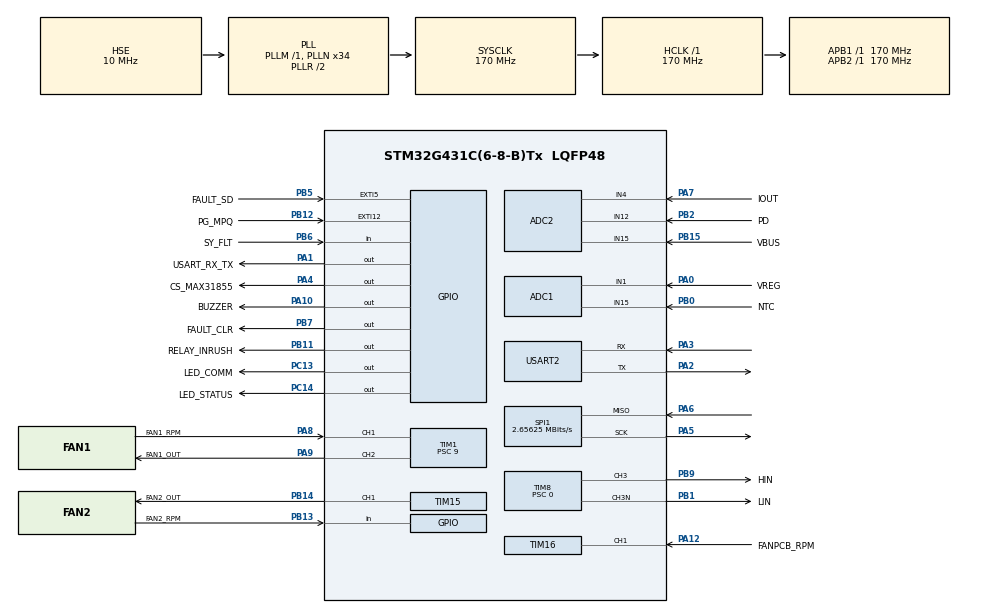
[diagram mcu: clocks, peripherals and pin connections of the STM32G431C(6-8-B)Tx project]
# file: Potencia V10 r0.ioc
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ADC1.Channel-0\#ChannelRegularConversion=ADC_CHANNEL_1
ADC1.Channel-1\#ChannelRegularConversion=ADC_CHANNEL_15
ADC1.ContinuousConvMode=ENABLE
ADC1.DMAContinuousRequests=ENABLE
ADC1.EOCSelection=ADC_EOC_SEQ_CONV
ADC1.LowPowerAutoWait=DISABLE
ADC1.NbrOfConversion=2
ADC1.NbrOfConversionFlag=1
ADC1.OffsetNumber-0\#ChannelRegularConversion=ADC_OFFSET_NONE
ADC1.OffsetNumber-1\#ChannelRegularConversion=ADC_OFFSET_NONE
ADC1.Overrun=ADC_OVR_DATA_OVERWRITTEN
ADC1.Rank-0\#ChannelRegularConversion=1
ADC1.Rank-1\#ChannelRegularConversion=2
ADC1.SamplingTime-0\#ChannelRegularConversion=ADC_SAMPLETIME_247CYCLES_5
ADC1.SamplingTime-1\#ChannelRegularConversion=ADC_SAMPLETIME_247CYCLES_5
ADC1.master=1
ADC2.Channel-0\#ChannelRegularConversion=ADC_CHANNEL_4
ADC2.Channel-1\#ChannelRegularConversion=ADC_CHANNEL_12
ADC2.Channel-2\#ChannelRegularConversion=ADC_CHANNEL_15
ADC2.ContinuousConvMode=ENABLE
ADC2.DMAContinuousRequests=ENABLE
ADC2.EOCSelection=ADC_EOC_SEQ_CONV
ADC2.NbrOfConversion=3
ADC2.NbrOfConversionFlag=1
ADC2.OffsetNumber-0\#ChannelRegularConversion=ADC_OFFSET_NONE
ADC2.OffsetNumber-1\#ChannelRegularConversion=ADC_OFFSET_NONE
ADC2.OffsetNumber-2\#ChannelRegularConversion=ADC_OFFSET_NONE
ADC2.Overrun=ADC_OVR_DATA_OVERWRITTEN
ADC2.Rank-0\#ChannelRegularConversion=1
ADC2.Rank-1\#ChannelRegularConversion=2
ADC2.Rank-2\#ChannelRegularConversion=3
ADC2.SamplingTime-0\#ChannelRegularConversion=ADC_SAMPLETIME_92CYCLES_5
ADC2.SamplingTime-1\#ChannelRegularConversion=ADC_SAMPLETIME_92CYCLES_5
ADC2.SamplingTime-2\#ChannelRegularConversion=ADC_SAMPLETIME_92CYCLES_5
Dma.ADC1.0.Direction=DMA_PERIPH_TO_MEMORY
Dma.ADC1.0.EventEnable=DISABLE
Dma.ADC1.0.Instance=DMA1_Channel1
Dma.ADC1.0.MemDataAlignment=DMA_MDATAALIGN_WORD
Dma.ADC1.0.MemInc=DMA_MINC_ENABLE
Dma.ADC1.0.Mode=DMA_CIRCULAR
Dma.ADC1.0.PeriphDataAlignment=DMA_PDATAALIGN_WORD
Dma.ADC1.0.PeriphInc=DMA_PINC_DISABLE
Dma.ADC1.0.Polarity=HAL_DMAMUX_REQ_GEN_RISING
Dma.ADC1.0.Priority=DMA_PRIORITY_LOW
Dma.ADC1.0.RequestNumber=1
Dma.ADC1.0.SignalID=NONE
Dma.ADC1.0.SyncEnable=DISABLE
Dma.ADC1.0.SyncPolarity=HAL_DMAMUX_SYNC_NO_EVENT
Dma.ADC1.0.SyncRequestNumber=1
Dma.ADC1.0.SyncSignalID=NONE
Dma.ADC2.1.Direction=DMA_PERIPH_TO_MEMORY
Dma.ADC2.1.EventEnable=DISABLE
Dma.ADC2.1.Instance=DMA1_Channel2
Dma.ADC2.1.MemDataAlignment=DMA_MDATAALIGN_WORD
Dma.ADC2.1.MemInc=DMA_MINC_ENABLE
Dma.ADC2.1.Mode=DMA_CIRCULAR
Dma.ADC2.1.PeriphDataAlignment=DMA_PDATAALIGN_WORD
Dma.ADC2.1.PeriphInc=DMA_PINC_DISABLE
Dma.ADC2.1.Polarity=HAL_DMAMUX_REQ_GEN_RISING
Dma.ADC2.1.Priority=DMA_PRIORITY_LOW
Dma.ADC2.1.RequestNumber=1
Dma.ADC2.1.SignalID=NONE
Dma.ADC2.1.SyncEnable=DISABLE
Dma.ADC2.1.SyncPolarity=HAL_DMAMUX_SYNC_NO_EVENT
Dma.ADC2.1.SyncRequestNumber=1
Dma.ADC2.1.SyncSignalID=NONE
Dma.Request0=ADC1
Dma.Request1=ADC2
Dma.Request2=SPI1_RX
Dma.Request3=USART2_RX
Dma.Request4=USART2_TX
Dma.SPI1_RX.2.Direction=DMA_PERIPH_TO_MEMORY
Dma.SPI1_RX.2.EventEnable=DISABLE
Dma.SPI1_RX.2.Instance=DMA1_Channel3
Dma.SPI1_RX.2.MemDataAlignment=DMA_MDATAALIGN_BYTE
Dma.SPI1_RX.2.MemInc=DMA_MINC_ENABLE
Dma.SPI1_RX.2.Mode=DMA_NORMAL
Dma.SPI1_RX.2.PeriphDataAlignment=DMA_PDATAALIGN_BYTE
Dma.SPI1_RX.2.PeriphInc=DMA_PINC_DISABLE
Dma.SPI1_RX.2.Polarity=HAL_DMAMUX_REQ_GEN_RISING
Dma.SPI1_RX.2.Priority=DMA_PRIORITY_LOW
Dma.SPI1_RX.2.RequestNumber=1
Dma.SPI1_RX.2.SignalID=NONE
Dma.SPI1_RX.2.SyncEnable=DISABLE
Dma.SPI1_RX.2.SyncPolarity=HAL_DMAMUX_SYNC_NO_EVENT
Dma.SPI1_RX.2.SyncRequestNumber=1
Dma.SPI1_RX.2.SyncSignalID=NONE
Dma.USART2_RX.3.Direction=DMA_PERIPH_TO_MEMORY
Dma.USART2_RX.3.EventEnable=DISABLE
Dma.USART2_RX.3.Instance=DMA2_Channel1
Dma.USART2_RX.3.MemDataAlignment=DMA_MDATAALIGN_BYTE
Dma.USART2_RX.3.MemInc=DMA_MINC_ENABLE
Dma.USART2_RX.3.Mode=DMA_CIRCULAR
Dma.USART2_RX.3.PeriphDataAlignment=DMA_PDATAALIGN_BYTE
Dma.USART2_RX.3.PeriphInc=DMA_PINC_DISABLE
Dma.USART2_RX.3.Polarity=HAL_DMAMUX_REQ_GEN_RISING
Dma.USART2_RX.3.Priority=DMA_PRIORITY_HIGH
Dma.USART2_RX.3.RequestNumber=1
Dma.USART2_RX.3.SignalID=NONE
Dma.USART2_RX.3.SyncEnable=DISABLE
Dma.USART2_RX.3.SyncPolarity=HAL_DMAMUX_SYNC_NO_EVENT
Dma.USART2_RX.3.SyncRequestNumber=1
Dma.USART2_RX.3.SyncSignalID=NONE
Dma.USART2_TX.4.Direction=DMA_MEMORY_TO_PERIPH
Dma.USART2_TX.4.EventEnable=DISABLE
Dma.USART2_TX.4.Instance=DMA2_Channel2
Dma.USART2_TX.4.MemDataAlignment=DMA_MDATAALIGN_BYTE
Dma.USART2_TX.4.MemInc=DMA_MINC_ENABLE
Dma.USART2_TX.4.Mode=DMA_NORMAL
Dma.USART2_TX.4.PeriphDataAlignment=DMA_PDATAALIGN_BYTE
Dma.USART2_TX.4.PeriphInc=DMA_PINC_DISABLE
Dma.USART2_TX.4.Polarity=HAL_DMAMUX_REQ_GEN_RISING
Dma.USART2_TX.4.Priority=DMA_PRIORITY_HIGH
Dma.USART2_TX.4.RequestNumber=1
Dma.USART2_TX.4.SignalID=NONE
Dma.USART2_TX.4.SyncEnable=DISABLE
Dma.USART2_TX.4.SyncPolarity=HAL_DMAMUX_SYNC_NO_EVENT
Dma.USART2_TX.4.SyncRequestNumber=1
Dma.USART2_TX.4.SyncSignalID=NONE
Mcu.Family=STM32G4
Mcu.Name=STM32G431C(6-8-B)Tx
Mcu.Package=LQFP48
NVIC.DMA1_Channel1_IRQn=true\:0\:0\:false\:false\:true\:false\:true\:true
NVIC.DMA1_Channel2_IRQn=true\:0\:0\:false\:false\:true\:false\:true\:true
NVIC.DMA1_Channel3_IRQn=true\:0\:0\:false\:false\:true\:false\:true\:true
NVIC.DMA2_Channel1_IRQn=true\:0\:0\:false\:false\:true\:false\:true\:true
NVIC.DMA2_Channel2_IRQn=true\:0\:0\:false\:false\:true\:false\:true\:true
NVIC.EXTI15_10_IRQn=true\:0\:0\:false\:false\:true\:true\:true\:true
NVIC.EXTI9_5_IRQn=true\:0\:0\:false\:false\:true\:true\:true\:true
NVIC.PVD_PVM_IRQn=true\:0\:0\:false\:false\:true\:true\:true\:true
NVIC.PriorityGroup=NVIC_PRIORITYGROUP_4
NVIC.TIM1_UP_TIM16_IRQn=true\:0\:0\:true\:false\:true\:true\:true\:true
NVIC.TIM2_IRQn=true\:0\:0\:false\:false\:true\:true\:true\:true
NVIC.USART2_IRQn=true\:0\:0\:false\:false\:true\:true\:true\:true
PA0.GPIO_Label=VREG
PA0.Mode=IN1-Single-Ended
PA0.Signal=ADC1_IN1
PA1.GPIO_Label=USART_RX_TX
PA1.Signal=GPIO_Output
PA10.GPIO_Label=BUZZER
PA10.Signal=GPIO_Output
PA12.GPIO_Label=FANPCB_RPM
PA12.Signal=S_TIM16_CH1
PA13.Mode=Trace_Asynchronous_SW
PA13.Signal=SYS_JTMS-SWDIO
PA14.Mode=Trace_Asynchronous_SW
PA14.Signal=SYS_JTCK-SWCLK
PA2.Mode=Asynchronous
PA2.Signal=USART2_TX
PA3.Mode=Asynchronous
PA3.Signal=USART2_RX
PA4.GPIO_Label=CS_MAX31855
PA4.PinState=GPIO_PIN_SET
PA4.Signal=GPIO_Output
PA5.Mode=RX_Only_Simplex_Unidirect_Master
PA5.Signal=SPI1_SCK
PA6.Mode=RX_Only_Simplex_Unidirect_Master
PA6.Signal=SPI1_MISO
PA7.GPIO_Label=IOUT
PA7.Mode=IN4-Single-Ended
PA7.Signal=ADC2_IN4
PA8.GPIO_Label=FAN1_RPM
PA8.Signal=S_TIM1_CH1
PA9.GPIO_Label=FAN1_OUT
PA9.Signal=S_TIM1_CH2
PB0.GPIO_Label=NTC
PB0.Mode=IN15-Single-Ended
PB0.Signal=ADC1_IN15
PB1.GPIO_Label=LIN
PB1.Mode=PWM Generation3 CH3 CH3N
PB1.Signal=TIM8_CH3N
PB11.GPIO_Label=RELAY_INRUSH
PB11.Signal=GPIO_Output
PB12.GPIO_Label=PG_MPQ
PB12.GPIO_ModeDefaultEXTI=GPIO_MODE_IT_FALLING
PB12.Signal=GPXTI12
PB13.GPIO_Label=FAN2_RPM
PB13.Signal=GPIO_Input
PB14.GPIO_Label=FAN2_OUT
PB14.Signal=S_TIM15_CH1
PB15.GPIO_Label=VBUS
PB15.Mode=IN15-Single-Ended
PB15.Signal=ADC2_IN15
PB2.GPIO_Label=PD
PB2.Mode=IN12-Single-Ended
PB2.Signal=ADC2_IN12
PB3.Mode=Trace_Asynchronous_SW
PB3.Signal=SYS_JTDO-SWO
PB5.GPIO_Label=FAULT_SD
PB5.GPIO_ModeDefaultEXTI=GPIO_MODE_IT_FALLING
PB5.Signal=GPXTI5
PB6.GPIO_Label=SY_FLT
PB6.Signal=GPIO_Input
PB7.GPIO_Label=FAULT_CLR
PB7.PinState=GPIO_PIN_SET
PB7.Signal=GPIO_Output
PB9.GPIO_Label=HIN
PB9.Signal=S_TIM8_CH3
PC13.GPIO_Label=LED_COMM
PC13.Signal=GPIO_Output
PC14-OSC32_IN.GPIO_Label=LED_STATUS
PC14-OSC32_IN.Signal=GPIO_Output
PF0-OSC_IN.Mode=HSE-External-Oscillator
PF0-OSC_IN.Signal=RCC_OSC_IN
PF1-OSC_OUT.Mode=HSE-External-Oscillator
PF1-OSC_OUT.Signal=RCC_OSC_OUT
ProjectManager.HeapSize=0x200
ProjectManager.StackSize=0x400
ProjectManager.TargetToolchain=STM32CubeIDE
RCC.ADC12Freq_Value=170000000
RCC.AHBFreq_Value=170000000
RCC.APB1Freq_Value=170000000
RCC.APB1TimFreq_Value=170000000
RCC.APB2Freq_Value=170000000
RCC.APB2TimFreq_Value=170000000
RCC.CortexFreq_Value=170000000
RCC.EXTERNAL_CLOCK_VALUE=12288000
RCC.HCLKFreq_Value=170000000
RCC.HSE_VALUE=10000000
RCC.HSI48_VALUE=48000000
RCC.HSI_VALUE=16000000
RCC.LSE_VALUE=32768
RCC.PLLN=34
RCC.PLLSourceVirtual=RCC_PLLSOURCE_HSE
RCC.SYSCLKFreq_VALUE=170000000
RCC.SYSCLKSource=RCC_SYSCLKSOURCE_PLLCLK
RCC.USBFreq_Value=170000000
RCC.VCOOutputFreq_Value=340000000
SH.S_TIM15_CH1.0=TIM15_CH1,PWM Generation1 CH1
SH.S_TIM16_CH1.0=TIM16_CH1,Input_Capture1_from_TI1
SH.S_TIM1_CH1.0=TIM1_CH1,Input_Capture1_from_TI1
SH.S_TIM1_CH2.0=TIM1_CH2,PWM Generation2 CH2
SH.S_TIM8_CH3.0=TIM8_CH3,PWM Generation3 CH3 CH3N
SPI1.BaudRatePrescaler=SPI_BAUDRATEPRESCALER_64
SPI1.CalculateBaudRate=2.65625 MBits/s
SPI1.DataSize=SPI_DATASIZE_8BIT
SPI1.Direction=SPI_DIRECTION_2LINES_RXONLY
SPI1.Mode=SPI_MODE_MASTER
SPI1.TIMode=SPI_TIMODE_DISABLE
SPI1.VirtualType=VM_MASTER
TIM1.Channel-Input_Capture1_from_TI1=TIM_CHANNEL_1
TIM1.Channel-PWM\ Generation2\ CH2=TIM_CHANNEL_2
TIM1.OC2Preload_PWM=DISABLE
TIM1.PeriodNoDither=16999
TIM1.Prescaler=9
TIM15.Channel-PWM\ Generation1\ CH1=TIM_CHANNEL_1
TIM15.OC1Preload_PWM=DISABLE
TIM15.PeriodNoDither=16999
TIM15.Prescaler=9
TIM16.AutoReloadPreload=TIM_AUTORELOAD_PRELOAD_ENABLE
TIM16.Channel=TIM_CHANNEL_1
TIM16.ClockDivision=TIM_CLOCKDIVISION_DIV4
TIM16.ICPrescaler=TIM_ICPSC_DIV1
TIM2.PeriodNoDither=99
TIM2.Prescaler=1700
TIM8.AutoReloadPreload=TIM_AUTORELOAD_PRELOAD_DISABLE
TIM8.Channel-PWM\ Generation3\ CH3\ CH3N=TIM_CHANNEL_3
TIM8.DeadTime=1
TIM8.OC3Preload_PWM=DISABLE
TIM8.OCFastMode_PWM-PWM\ Generation3\ CH3\ CH3N=TIM_OCFAST_DISABLE
TIM8.OCMode_PWM-PWM\ Generation3\ CH3\ CH3N=TIM_OCMODE_PWM1
TIM8.PeriodNoDither=1700
TIM8.Prescaler=0
TIM8.PulseNoDither_3=100
USART2.VirtualMode-Asynchronous=VM_ASYNC
USART2.WordLength=WORDLENGTH_8B
VP_SYS_VS_DBSignals.Mode=DisableDeadBatterySignals
VP_TIM15_VS_ClockSourceINT.Mode=Internal
VP_TIM16_VS_ClockSourceINT.Mode=Enable_Timer
VP_TIM1_VS_ClockSourceINT.Mode=Internal
VP_TIM2_VS_ClockSourceINT.Mode=Internal
VP_TIM8_VS_ClockSourceINT.Mode=Internal
board=custom

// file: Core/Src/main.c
/* USER CODE BEGIN Header */
/**
 ******************************************************************************
 * @file           : main.c
 * @brief          : Main program body
 ******************************************************************************
 * @attention
 *
 * Copyright (c) 2022 STMicroelectronics.
 * All rights reserved.
 *
 * This software is licensed under terms that can be found in the LICENSE file
 * in the root directory of this software component.
 * If no LICENSE file comes with this software, it is provided AS-IS.
 *
 ******************************************************************************
 */
/* USER CODE END Header */
#include "main.h"

/* USER CODE BEGIN Includes */

#include <stdlib.h>
#include <string.h>
#include <stdbool.h>
#include <limits.h>

#include "NTC 10K 3989.h"
#include "Full Duplex USART r0.h"
#include "MAX31855 r0.h"
/* USER CODE END Includes */

/* USER CODE BEGIN PTD */

typedef union
{
	struct
	{
		unsigned Powerdown :1;
		unsigned Undervoltage :1;
		unsigned Overvoltage :1;
		unsigned MPQNpg :1;
		unsigned ErrorFanPcb :1;
		unsigned ErrorFan1 :1;
		unsigned Fault :1;
		unsigned ErrorNTCDissipator :1;
		unsigned Dummy :24;
	};
	uint32_t ExistError;
} t_FlagsErrors;

uint32_t SerialNumber;

volatile struct
{
	// PID Control
	int32_t kP;
	int32_t kI;
	int32_t kD;

	// Oven Config
	uint16_t MaxTemperatureOven;
	uint16_t MaxRPMFanOven;

	//PCB Config
	uint16_t MinVoltInput;
	uint16_t MaxVoltInput;

	uint16_t MinRPMFanPCB;
	uint16_t MaxTemperaturePCB;

} Config;
volatile struct
{
	uint16_t PowerVoltage; //
	uint16_t ControlVoltage; //
	uint16_t OutputVoltage; //
	uint16_t CurrentOutput; //

	int16_t TemperatureOven; //
	int16_t TemperaturePCB; //

	uint16_t FanRPMPCB; //
	uint16_t FanRPMOven1; //
	uint16_t FanRPMOven2; // todo: Include in new revision PCB

	uint32_t HourmeterHours; //
	uint8_t HourmeterMinutes; //

	t_FlagsErrors Errors; //
} Status;

volatile struct
{
	union
	{
		unsigned CalculateNTC :1;
		unsigned CalculatePD :1;
		unsigned CalculateVBUS :1;
		unsigned CalculateVREG :1;
		unsigned CalculateCURR :1;
		unsigned Error :5;
		unsigned Dummy :22;
	} Flags;
} sStatusPower;

enum
{
	ERROR_NONE = 0, ERROR_POWERDOWN, ERROR_UNDERVOLTAGE, ERROR_OVERVOLTAGE, ERROR_MPQ_NPG, //NPG = NOT POWER GOOD
	ERROR_FAN_PCB,
	ERROR_FAN1,
	ERROR_FAULT,
	ERROR_NTC_DISSIPATOR,
} eErros;

enum
{
	COMM_GET_STATUS = 0, COMM_GET_SERIAL_NUMBER,

	COMM_SET_CONFIGURATION, COMM_SET_SERIAL_NUMBER,
} eComm;

FD_t *FullDuplexSystem;

/* USER CODE END PTD */

/* USER CODE BEGIN PD */
/* ################# DEFINIÇÕES CÓDIGO	 	 ################# */

#define	HIGH			1
#define	LOW				0

/* ################# DEFINITIONS AD 		 ################# */
#define RES_AD			4095UL				// (2^12 - 1)
#define	VREF			33UL				//3,3V

/* ################# POWERDOWN DEFINITIONS 	 ################# */
#define POWERDOWN_VALUE 160 //16V
#define TIMEOUT_PD		500//ms
#define BUFFER_PD		10
#define RCIMA_PD		10000UL
#define RBAIXO_PD		1240UL
#define PD_MULT			((VREF * (RCIMA_PD + RBAIXO_PD))/((RES_AD * RBAIXO_PD)/PD_DIV))
#define PD_DIV			1000

/* ################# VBUS DEFINITIONS 		 ################# */
#define UNDERVOLTAGE_VALUE 		1000 		//100V
#define TIMEOUT_UNDERVOLTAGE	500			//ms
#define OVERVOLTAGE_VALUE 		1970 		//197V
#define TIMEOUT_OVERVOLTAGE		500			//ms
#define LOW_OPERATION	400					//40V
#define BUFFER_VBUS		10
#define RCIMA_VBUS		300000UL
#define RBAIXO_VBUS		3900UL
#define VBUS_MULT		((VREF * (RCIMA_VBUS + RBAIXO_VBUS))/((RES_AD * RBAIXO_VBUS) /VBUS_DIV))
#define VBUS_DIV		1000

/* ################# VREG DEFINITIONS 		 ################ */
#define BUFFER_VREG		10
#define RCIMA_VREG		300000UL
#define RBAIXO_VREG		3900UL
#define VREG_MULT		((VREF * (RCIMA_VREG + RBAIXO_VREG))/((RES_AD * RBAIXO_VREG) /VBUS_VREG))
#define VREG_DIV		1000

/* ################# CURR DEFINITIONS 		 ################# */
#define BUFFER_CURR		10
#define AD_0A			409 //bits //Todo: In future, change this value for calibration value
#define AD_SENSITIVY	124 //124 bits/A

/* ################# NTC DEFINITIONS 		 ################# */
#define	TEMPERATURE_SHORT_CIRCUIT	1200	//120°C
#define	TEMPERATURE_OPEN_CIRCUIT	-200	//-20°C
#define OVERTEMPERATURE_DISSIPATOR	800		//80°C
#define BUFFER_NTC	1000					//1000 leituras de AD

/* ################# DEFINITIONS GENERAL	 ################# */
#define PERIOD_LED					1000	//ms
#define PERIOD_LED_ERROR 			250		//ms
#define RELAY_INRUSH				300		//ms
#define FAN_PCB_TIMEOUT				5000	//ms
#define FAN_1_AND_2_TIMEOUT			5000	//ms

/* ################# COEFICIENTE ANGULAR SAIDA  ################# */
#define COEFF_A			1.0
#define COEFF_B			0.0

/* ################# DEFINES MAX31855  ################# */

/* USER CODE END PD */

ADC_HandleTypeDef hadc1;
ADC_HandleTypeDef hadc2;
DMA_HandleTypeDef hdma_adc1;
DMA_HandleTypeDef hdma_adc2;

SPI_HandleTypeDef hspi1;
DMA_HandleTypeDef hdma_spi1_rx;

TIM_HandleTypeDef htim1;
TIM_HandleTypeDef htim2;
TIM_HandleTypeDef htim8;
TIM_HandleTypeDef htim15;
TIM_HandleTypeDef htim16;

UART_HandleTypeDef huart2;
DMA_HandleTypeDef hdma_usart2_rx;
DMA_HandleTypeDef hdma_usart2_tx;

/* USER CODE BEGIN PV */
uint32_t Adc1Val[2], Adc2Val[3];
volatile uint16_t AdValuePD[BUFFER_PD] =
{ 0 }, AdValueVBUS[BUFFER_VBUS] =
{ 0 }, AdValueVREG[BUFFER_VREG] =
{ 0 }, AdValueNTC[BUFFER_NTC] =
{ 0 }, AdValueCURR[BUFFER_CURR] =
{ 0 };
uint16_t ValuePD = 0, ValueVBUS = 0, ValueVREG = 0;
int16_t ValueNTC = 0, ValueCURR = 0;
volatile uint16_t CntTimeoutPD = 0, CntTimeoutOvervoltage = 0, CntTimeoutUndervoltage = 0;
volatile uint8_t CntAdValuePD = 0, CntAdValueCURR = 0, CntAdValueVBUS = 0, CntAdValueVREG = 0, CntAdValueNTC = 0;
volatile uint16_t CntStatusLED = 0;
volatile uint16_t CntStatusLEDError = 0;
volatile uint16_t Cnt1ms = 0;
volatile uint32_t IC_FanPCB_Value1 = 0, IC_Fan1_Value1 = 0, IC_FanPCB_Value2 = 0, IC_Fan1_Value2 = 0, IC_FanPCB_Difference = 0, IC_Fan1_Difference = 0,
		IC_FanPCB_Frequency = 0, IC_Fan1_Frequency = 0;
volatile uint8_t IC_FanPCB_IsFirstCaptured = false, IC_Fan1_IsFirstCaptured = false;
volatile uint16_t IC_FanPCB_OvfTimer = 0, IC_Fan1_OvfTimer = 0, IC_FanPCB_RPM = 0, IC_Fan1_RPM = 0;
volatile uint16_t CntFanPCB = 0, CntFan1 = 0, CntRelayInrush = 0;
volatile uint8_t Cnt60s = 0;
/* USER CODE END PV */

void SystemClock_Config(void);
static void MX_GPIO_Init(void);
static void MX_DMA_Init(void);
static void MX_ADC1_Init(void);
static void MX_ADC2_Init(void);
static void MX_TIM2_Init(void);
static void MX_TIM16_Init(void);
static void MX_SPI1_Init(void);
static void MX_USART2_UART_Init(void);
static void MX_TIM8_Init(void);
static void MX_TIM1_Init(void);
static void MX_TIM15_Init(void);
/* USER CODE BEGIN PFP */
static void Hw_Buck_Init(void);
static void Hw_Buck_Deinit(void);
void HAL_GPIO_EXTI_Callback(uint16_t GPIO_Pin);
void HAL_TIM_PeriodElapsedCallback(TIM_HandleTypeDef *htim);
void DMACallbackADC1(DMA_HandleTypeDef *hdma);
void DMACallbackADC2(DMA_HandleTypeDef *hdma);

void HAL_TIM_IC_CaptureCallback(TIM_HandleTypeDef *htim);
static void StatusLEDControl(uint8_t ErrorCode);
static void SetOutputVoltage(uint16_t OutVoltage);
static void SetError(void);
/* USER CODE END PFP */

int main(void)
{

	/* MCU Configuration--------------------------------------------------------*/

	/* Reset of all peripherals, Initializes the Flash interface and the Systick. */
	HAL_Init();

	/* Configure the system clock */
	SystemClock_Config();

	/* Initialize all configured peripherals */
	MX_GPIO_Init();
	MX_DMA_Init();
	MX_ADC1_Init();
	MX_ADC2_Init();
	MX_TIM2_Init();
	MX_TIM16_Init();
	MX_SPI1_Init();
	MX_USART2_UART_Init();
	MX_TIM8_Init();
	MX_TIM1_Init();
	MX_TIM15_Init();
	/* USER CODE BEGIN 2 */
	HAL_ADCEx_Calibration_Start(&hadc1, ADC_SINGLE_ENDED); // Calibrate ADC
	HAL_ADCEx_Calibration_Start(&hadc2, ADC_SINGLE_ENDED); // Calibrate ADC

	HAL_TIM_Base_Start_IT(&htim2);

	HAL_ADC_Start_DMA(&hadc1, Adc1Val, 2); // Start the ADC in DMA mode
	HAL_ADC_Start_DMA(&hadc2, Adc2Val, 3); // Start the ADC in DMA mode

	hdma_adc1.XferCpltCallback = &DMACallbackADC1;
	hdma_adc2.XferCpltCallback = &DMACallbackADC2;

	HAL_TIM_Base_Start_IT(&htim16);
	HAL_TIM_Base_Start_IT(&htim1);

	HAL_TIM_IC_Start_IT(&htim16, TIM_CHANNEL_1);
	HAL_TIM_IC_Start_IT(&htim1, TIM_CHANNEL_1);

	HAL_TIM_PWM_Start(&htim8, TIM_CHANNEL_3); //PWM HIN e LIN
	HAL_TIMEx_PWMN_Start(&htim8, TIM_CHANNEL_3); // turn on complementary channel

	HAL_TIM_PWM_Start(&htim1, TIM_CHANNEL_2); //FAN1

	HAL_TIM_PWM_Start(&htim15, TIM_CHANNEL_1); //FAN2

	__HAL_TIM_SET_COMPARE(&htim1, TIM_CHANNEL_2, 0);
	__HAL_TIM_SET_COMPARE(&htim15, TIM_CHANNEL_1, 0);

	Hw_Buck_Init();
	Init_MAX31855(&hspi1, CS_MAX31855_GPIO_Port, CS_MAX31855_Pin);

	FD_CONFIG_t config;

	config.size_buffer = 50;
	config.uart = &huart2;

	HAL_GPIO_WritePin(USART_RX_TX_GPIO_Port, USART_RX_TX_Pin, HIGH);

	FullDuplexSystem = FDUSART_Init(&config);

	uint8_t *Buf = (uint8_t*) malloc(config.size_buffer * sizeof(uint8_t));
	if (Buf != NULL)
	{  // Sempre verifique se a alocação foi bem-sucedida
		memset(Buf, 0, config.size_buffer); // Inicializa a variavel com valor 0
	}
	else
	{
		// Tratamento de erro para falha de alocação de memória
	}
	/* USER CODE END 2 */

	/* Infinite loop */
	while (1)
	{

		/* USER CODE BEGIN 3 */
		size_t i = 0;
		uint32_t u32Temp = 0;
		if (sStatusPower.Flags.CalculatePD)
		{
			sStatusPower.Flags.CalculatePD = 0;
			i = 0;
			u32Temp = 0;
			for (i = 0; i < BUFFER_PD; i++)
			{
				u32Temp += AdValuePD[i];
			}
			ValuePD = u32Temp / BUFFER_PD;
			ValuePD = (uint16_t) (((uint32_t) ValuePD * (uint32_t) PD_MULT) / (uint32_t) PD_DIV);
			Status.ControlVoltage = ValuePD;
		}
		if (sStatusPower.Flags.CalculateVBUS)
		{

			sStatusPower.Flags.CalculateVBUS = false;
			i = 0;
			u32Temp = 0;
			for (i = 0; i < BUFFER_VBUS; i++)
			{
				u32Temp += AdValueVBUS[i];
			}
			ValueVBUS = u32Temp / BUFFER_VBUS;
			ValueVBUS = (uint16_t) (((uint32_t) ValueVBUS * (uint32_t) VBUS_MULT) / (uint32_t) VBUS_DIV);
			Status.PowerVoltage = ValueVBUS;
		}
		if (sStatusPower.Flags.CalculateVREG)
		{
			sStatusPower.Flags.CalculateVREG = false;
			i = 0;
			u32Temp = 0;
			for (i = 0; i < BUFFER_VREG; i++)
			{
				u32Temp += AdValueVREG[i];
			}
			ValueVREG = u32Temp / BUFFER_VREG;
			ValueVREG = (uint16_t) (((uint32_t) ValueVREG * (uint32_t) VREG_MULT) / (uint32_t) VREG_DIV);
			Status.OutputVoltage = ValueVREG;
		}
		if (sStatusPower.Flags.CalculateCURR)
		{
			sStatusPower.Flags.CalculateCURR = false;
			i = 0;
			u32Temp = 0;
			for (i = 0; i < BUFFER_CURR; i++)
			{
				u32Temp += AdValueCURR[i];
			}
			//float CurrInVolt = (float)((float)((float)((float)u32Temp / (float)BUFFER_CURR)*(float)VREF)/(float)RES_AD);
			//float CurrOffsetInVolt = GAIN_CURR * VS_TMCS1107A2U;
			float CurrInAD = (float) ((float) u32Temp / (float) BUFFER_CURR) - AD_0A;
			float CurrInAmp = (float) CurrInAD / AD_SENSITIVY;
			Status.CurrentOutput = ((float) CurrInAmp * (float) 100.0);
		}
		if (sStatusPower.Flags.CalculateNTC)
		{
			sStatusPower.Flags.CalculateNTC = false;
			i = 0;
			u32Temp = 0;
			for (i = 0; i < BUFFER_NTC; i++)
			{
				u32Temp += AdValueNTC[i];
			}
			ValueNTC = u32Temp / BUFFER_NTC;

			ValueNTC = NTC_TABLE[ValueNTC / 4]; // Divide por 4 pois a tabela é de 1024 pontos e o AD de 4096 --> 4096/1024 = 4

			Status.TemperaturePCB = ValueNTC;

			if (ValueNTC > TEMPERATURE_SHORT_CIRCUIT || ValueNTC < TEMPERATURE_OPEN_CIRCUIT)
			{
				Status.Errors.ErrorNTCDissipator = true;
			}
			else
			{
				Status.Errors.ErrorNTCDissipator = false;
			}
		}
		SetOutputVoltage(1002);
		__HAL_TIM_SET_COMPARE(&htim1, TIM_CHANNEL_2, 16000);
		__HAL_TIM_SET_COMPARE(&htim15, TIM_CHANNEL_1, 16000);

		uint8_t Cmd;

		size_t Len;
		if (FDUSART_Receive_Message(FullDuplexSystem, &Cmd, Buf, &Len))
		{
			HAL_GPIO_TogglePin(LED_COMM_GPIO_Port, LED_COMM_Pin);

			switch (Cmd)
			{
				case COMM_GET_SERIAL_NUMBER:
				{
					FDUSART_SendMessage(FullDuplexSystem, COMM_GET_SERIAL_NUMBER, (uint8_t*) &Config, sizeof(Config));
				}
					break;
				case COMM_SET_CONFIGURATION:
				{
					Config = Buf;
				}
					break;
				case COMM_SET_SERIAL_NUMBER:
				{
					SerialNumber = Buf;
					//Todo: Save in Flash Serial Number
				}
					break;

				default:
				{

				}
				break;
			}
		}

	}
	/* USER CODE END 3 */
}

void SystemClock_Config(void)
{
	RCC_OscInitTypeDef RCC_OscInitStruct =
	{ 0 };
	RCC_ClkInitTypeDef RCC_ClkInitStruct =
	{ 0 };

	/** Configure the main internal regulator output voltage
	 */
	HAL_PWREx_ControlVoltageScaling(PWR_REGULATOR_VOLTAGE_SCALE1_BOOST);

	/** Initializes the RCC Oscillators according to the specified parameters
	 * in the RCC_OscInitTypeDef structure.
	 */
	RCC_OscInitStruct.OscillatorType = RCC_OSCILLATORTYPE_HSE;
	RCC_OscInitStruct.HSEState = RCC_HSE_ON;
	RCC_OscInitStruct.PLL.PLLState = RCC_PLL_ON;
	RCC_OscInitStruct.PLL.PLLSource = RCC_PLLSOURCE_HSE;
	RCC_OscInitStruct.PLL.PLLM = RCC_PLLM_DIV1;
	RCC_OscInitStruct.PLL.PLLN = 34;
	RCC_OscInitStruct.PLL.PLLP = RCC_PLLP_DIV2;
	RCC_OscInitStruct.PLL.PLLQ = RCC_PLLQ_DIV2;
	RCC_OscInitStruct.PLL.PLLR = RCC_PLLR_DIV2;
	if (HAL_RCC_OscConfig(&RCC_OscInitStruct) != HAL_OK)
	{
		Error_Handler();
	}

	/** Initializes the CPU, AHB and APB buses clocks
	 */
	RCC_ClkInitStruct.ClockType = RCC_CLOCKTYPE_HCLK | RCC_CLOCKTYPE_SYSCLK | RCC_CLOCKTYPE_PCLK1 | RCC_CLOCKTYPE_PCLK2;
	RCC_ClkInitStruct.SYSCLKSource = RCC_SYSCLKSOURCE_PLLCLK;
	RCC_ClkInitStruct.AHBCLKDivider = RCC_SYSCLK_DIV1;
	RCC_ClkInitStruct.APB1CLKDivider = RCC_HCLK_DIV1;
	RCC_ClkInitStruct.APB2CLKDivider = RCC_HCLK_DIV1;

	if (HAL_RCC_ClockConfig(&RCC_ClkInitStruct, FLASH_LATENCY_4) != HAL_OK)
	{
		Error_Handler();
	}
}

static void MX_ADC1_Init(void)
{

	ADC_MultiModeTypeDef multimode =
	{ 0 };
	ADC_ChannelConfTypeDef sConfig =
	{ 0 };

	/** Common config
	 */
	hadc1.Instance = ADC1;
	hadc1.Init.ClockPrescaler = ADC_CLOCK_SYNC_PCLK_DIV4;
	hadc1.Init.Resolution = ADC_RESOLUTION_12B;
	hadc1.Init.DataAlign = ADC_DATAALIGN_RIGHT;
	hadc1.Init.GainCompensation = 0;
	hadc1.Init.ScanConvMode = ADC_SCAN_ENABLE;
	hadc1.Init.EOCSelection = ADC_EOC_SEQ_CONV;
	hadc1.Init.LowPowerAutoWait = DISABLE;
	hadc1.Init.ContinuousConvMode = ENABLE;
	hadc1.Init.NbrOfConversion = 2;
	hadc1.Init.DiscontinuousConvMode = DISABLE;
	hadc1.Init.ExternalTrigConv = ADC_SOFTWARE_START;
	hadc1.Init.ExternalTrigConvEdge = ADC_EXTERNALTRIGCONVEDGE_NONE;
	hadc1.Init.DMAContinuousRequests = ENABLE;
	hadc1.Init.Overrun = ADC_OVR_DATA_OVERWRITTEN;
	hadc1.Init.OversamplingMode = DISABLE;
	if (HAL_ADC_Init(&hadc1) != HAL_OK)
	{
		Error_Handler();
	}

	/** Configure the ADC multi-mode
	 */
	multimode.Mode = ADC_MODE_INDEPENDENT;
	if (HAL_ADCEx_MultiModeConfigChannel(&hadc1, &multimode) != HAL_OK)
	{
		Error_Handler();
	}

	/** Configure Regular Channel
	 */
	sConfig.Channel = ADC_CHANNEL_1;
	sConfig.Rank = ADC_REGULAR_RANK_1;
	sConfig.SamplingTime = ADC_SAMPLETIME_247CYCLES_5;
	sConfig.SingleDiff = ADC_SINGLE_ENDED;
	sConfig.OffsetNumber = ADC_OFFSET_NONE;
	sConfig.Offset = 0;
	if (HAL_ADC_ConfigChannel(&hadc1, &sConfig) != HAL_OK)
	{
		Error_Handler();
	}

	/** Configure Regular Channel
	 */
	sConfig.Channel = ADC_CHANNEL_15;
	sConfig.Rank = ADC_REGULAR_RANK_2;
	if (HAL_ADC_ConfigChannel(&hadc1, &sConfig) != HAL_OK)
	{
		Error_Handler();
	}

}

static void MX_ADC2_Init(void)
{

	ADC_ChannelConfTypeDef sConfig =
	{ 0 };

	/** Common config
	 */
	hadc2.Instance = ADC2;
	hadc2.Init.ClockPrescaler = ADC_CLOCK_SYNC_PCLK_DIV4;
	hadc2.Init.Resolution = ADC_RESOLUTION_12B;
	hadc2.Init.DataAlign = ADC_DATAALIGN_RIGHT;
	hadc2.Init.GainCompensation = 0;
	hadc2.Init.ScanConvMode = ADC_SCAN_ENABLE;
	hadc2.Init.EOCSelection = ADC_EOC_SEQ_CONV;
	hadc2.Init.LowPowerAutoWait = DISABLE;
	hadc2.Init.ContinuousConvMode = ENABLE;
	hadc2.Init.NbrOfConversion = 3;
	hadc2.Init.DiscontinuousConvMode = DISABLE;
	hadc2.Init.ExternalTrigConv = ADC_SOFTWARE_START;
	hadc2.Init.ExternalTrigConvEdge = ADC_EXTERNALTRIGCONVEDGE_NONE;
	hadc2.Init.DMAContinuousRequests = ENABLE;
	hadc2.Init.Overrun = ADC_OVR_DATA_OVERWRITTEN;
	hadc2.Init.OversamplingMode = DISABLE;
	if (HAL_ADC_Init(&hadc2) != HAL_OK)
	{
		Error_Handler();
	}

	/** Configure Regular Channel
	 */
	sConfig.Channel = ADC_CHANNEL_4;
	sConfig.Rank = ADC_REGULAR_RANK_1;
	sConfig.SamplingTime = ADC_SAMPLETIME_92CYCLES_5;
	sConfig.SingleDiff = ADC_SINGLE_ENDED;
	sConfig.OffsetNumber = ADC_OFFSET_NONE;
	sConfig.Offset = 0;
	if (HAL_ADC_ConfigChannel(&hadc2, &sConfig) != HAL_OK)
	{
		Error_Handler();
	}

	/** Configure Regular Channel
	 */
	sConfig.Channel = ADC_CHANNEL_12;
	sConfig.Rank = ADC_REGULAR_RANK_2;
	if (HAL_ADC_ConfigChannel(&hadc2, &sConfig) != HAL_OK)
	{
		Error_Handler();
	}

	/** Configure Regular Channel
	 */
	sConfig.Channel = ADC_CHANNEL_15;
	sConfig.Rank = ADC_REGULAR_RANK_3;
	if (HAL_ADC_ConfigChannel(&hadc2, &sConfig) != HAL_OK)
	{
		Error_Handler();
	}

}

static void MX_SPI1_Init(void)
{

	/* SPI1 parameter configuration*/
	hspi1.Instance = SPI1;
	hspi1.Init.Mode = SPI_MODE_MASTER;
	hspi1.Init.Direction = SPI_DIRECTION_2LINES_RXONLY;
	hspi1.Init.DataSize = SPI_DATASIZE_8BIT;
	hspi1.Init.CLKPolarity = SPI_POLARITY_LOW;
	hspi1.Init.CLKPhase = SPI_PHASE_1EDGE;
	hspi1.Init.NSS = SPI_NSS_SOFT;
	hspi1.Init.BaudRatePrescaler = SPI_BAUDRATEPRESCALER_64;
	hspi1.Init.FirstBit = SPI_FIRSTBIT_MSB;
	hspi1.Init.TIMode = SPI_TIMODE_DISABLE;
	hspi1.Init.CRCCalculation = SPI_CRCCALCULATION_DISABLE;
	hspi1.Init.CRCPolynomial = 7;
	hspi1.Init.CRCLength = SPI_CRC_LENGTH_DATASIZE;
	hspi1.Init.NSSPMode = SPI_NSS_PULSE_ENABLE;
	if (HAL_SPI_Init(&hspi1) != HAL_OK)
	{
		Error_Handler();
	}

}

static void MX_TIM1_Init(void)
{

	TIM_ClockConfigTypeDef sClockSourceConfig =
	{ 0 };
	TIM_MasterConfigTypeDef sMasterConfig =
	{ 0 };
	TIM_IC_InitTypeDef sConfigIC =
	{ 0 };
	TIM_OC_InitTypeDef sConfigOC =
	{ 0 };
	TIM_BreakDeadTimeConfigTypeDef sBreakDeadTimeConfig =
	{ 0 };

	htim1.Instance = TIM1;
	htim1.Init.Prescaler = 9;
	htim1.Init.CounterMode = TIM_COUNTERMODE_UP;
	htim1.Init.Period = 16999;
	htim1.Init.ClockDivision = TIM_CLOCKDIVISION_DIV1;
	htim1.Init.RepetitionCounter = 0;
	htim1.Init.AutoReloadPreload = TIM_AUTORELOAD_PRELOAD_DISABLE;
	if (HAL_TIM_Base_Init(&htim1) != HAL_OK)
	{
		Error_Handler();
	}
	sClockSourceConfig.ClockSource = TIM_CLOCKSOURCE_INTERNAL;
	if (HAL_TIM_ConfigClockSource(&htim1, &sClockSourceConfig) != HAL_OK)
	{
		Error_Handler();
	}
	if (HAL_TIM_IC_Init(&htim1) != HAL_OK)
	{
		Error_Handler();
	}
	if (HAL_TIM_PWM_Init(&htim1) != HAL_OK)
	{
		Error_Handler();
	}
	sMasterConfig.MasterOutputTrigger = TIM_TRGO_RESET;
	sMasterConfig.MasterOutputTrigger2 = TIM_TRGO2_RESET;
	sMasterConfig.MasterSlaveMode = TIM_MASTERSLAVEMODE_DISABLE;
	if (HAL_TIMEx_MasterConfigSynchronization(&htim1, &sMasterConfig) != HAL_OK)
	{
		Error_Handler();
	}
	sConfigIC.ICPolarity = TIM_INPUTCHANNELPOLARITY_RISING;
	sConfigIC.ICSelection = TIM_ICSELECTION_DIRECTTI;
	sConfigIC.ICPrescaler = TIM_ICPSC_DIV1;
	sConfigIC.ICFilter = 0;
	if (HAL_TIM_IC_ConfigChannel(&htim1, &sConfigIC, TIM_CHANNEL_1) != HAL_OK)
	{
		Error_Handler();
	}
	sConfigOC.OCMode = TIM_OCMODE_PWM1;
	sConfigOC.Pulse = 0;
	sConfigOC.OCPolarity = TIM_OCPOLARITY_HIGH;
	sConfigOC.OCNPolarity = TIM_OCNPOLARITY_HIGH;
	sConfigOC.OCFastMode = TIM_OCFAST_DISABLE;
	sConfigOC.OCIdleState = TIM_OCIDLESTATE_RESET;
	sConfigOC.OCNIdleState = TIM_OCNIDLESTATE_RESET;
	if (HAL_TIM_PWM_ConfigChannel(&htim1, &sConfigOC, TIM_CHANNEL_2) != HAL_OK)
	{
		Error_Handler();
	}
	__HAL_TIM_DISABLE_OCxPRELOAD(&htim1, TIM_CHANNEL_2);
	sBreakDeadTimeConfig.OffStateRunMode = TIM_OSSR_DISABLE;
	sBreakDeadTimeConfig.OffStateIDLEMode = TIM_OSSI_DISABLE;
	sBreakDeadTimeConfig.LockLevel = TIM_LOCKLEVEL_OFF;
	sBreakDeadTimeConfig.DeadTime = 0;
	sBreakDeadTimeConfig.BreakState = TIM_BREAK_DISABLE;
	sBreakDeadTimeConfig.BreakPolarity = TIM_BREAKPOLARITY_HIGH;
	sBreakDeadTimeConfig.BreakFilter = 0;
	sBreakDeadTimeConfig.BreakAFMode = TIM_BREAK_AFMODE_INPUT;
	sBreakDeadTimeConfig.Break2State = TIM_BREAK2_DISABLE;
	sBreakDeadTimeConfig.Break2Polarity = TIM_BREAK2POLARITY_HIGH;
	sBreakDeadTimeConfig.Break2Filter = 0;
	sBreakDeadTimeConfig.Break2AFMode = TIM_BREAK_AFMODE_INPUT;
	sBreakDeadTimeConfig.AutomaticOutput = TIM_AUTOMATICOUTPUT_DISABLE;
	if (HAL_TIMEx_ConfigBreakDeadTime(&htim1, &sBreakDeadTimeConfig) != HAL_OK)
	{
		Error_Handler();
	}
	HAL_TIM_MspPostInit(&htim1);

}

static void MX_TIM2_Init(void)
{

	TIM_ClockConfigTypeDef sClockSourceConfig =
	{ 0 };
	TIM_MasterConfigTypeDef sMasterConfig =
	{ 0 };

	htim2.Instance = TIM2;
	htim2.Init.Prescaler = 1700;
	htim2.Init.CounterMode = TIM_COUNTERMODE_UP;
	htim2.Init.Period = 99;
	htim2.Init.ClockDivision = TIM_CLOCKDIVISION_DIV1;
	htim2.Init.AutoReloadPreload = TIM_AUTORELOAD_PRELOAD_DISABLE;
	if (HAL_TIM_Base_Init(&htim2) != HAL_OK)
	{
		Error_Handler();
	}
	sClockSourceConfig.ClockSource = TIM_CLOCKSOURCE_INTERNAL;
	if (HAL_TIM_ConfigClockSource(&htim2, &sClockSourceConfig) != HAL_OK)
	{
		Error_Handler();
	}
	sMasterConfig.MasterOutputTrigger = TIM_TRGO_RESET;
	sMasterConfig.MasterSlaveMode = TIM_MASTERSLAVEMODE_DISABLE;
	if (HAL_TIMEx_MasterConfigSynchronization(&htim2, &sMasterConfig) != HAL_OK)
	{
		Error_Handler();
	}

}

static void MX_TIM8_Init(void)
{

	TIM_ClockConfigTypeDef sClockSourceConfig =
	{ 0 };
	TIM_MasterConfigTypeDef sMasterConfig =
	{ 0 };
	TIM_OC_InitTypeDef sConfigOC =
	{ 0 };
	TIM_BreakDeadTimeConfigTypeDef sBreakDeadTimeConfig =
	{ 0 };

	htim8.Instance = TIM8;
	htim8.Init.Prescaler = 0;
	htim8.Init.CounterMode = TIM_COUNTERMODE_UP;
	htim8.Init.Period = 1700;
	htim8.Init.ClockDivision = TIM_CLOCKDIVISION_DIV1;
	htim8.Init.RepetitionCounter = 0;
	htim8.Init.AutoReloadPreload = TIM_AUTORELOAD_PRELOAD_DISABLE;
	if (HAL_TIM_Base_Init(&htim8) != HAL_OK)
	{
		Error_Handler();
	}
	sClockSourceConfig.ClockSource = TIM_CLOCKSOURCE_INTERNAL;
	if (HAL_TIM_ConfigClockSource(&htim8, &sClockSourceConfig) != HAL_OK)
	{
		Error_Handler();
	}
	if (HAL_TIM_PWM_Init(&htim8) != HAL_OK)
	{
		Error_Handler();
	}
	sMasterConfig.MasterOutputTrigger = TIM_TRGO_RESET;
	sMasterConfig.MasterOutputTrigger2 = TIM_TRGO2_RESET;
	sMasterConfig.MasterSlaveMode = TIM_MASTERSLAVEMODE_DISABLE;
	if (HAL_TIMEx_MasterConfigSynchronization(&htim8, &sMasterConfig) != HAL_OK)
	{
		Error_Handler();
	}
	sConfigOC.OCMode = TIM_OCMODE_PWM1;
	sConfigOC.Pulse = 100;
	sConfigOC.OCPolarity = TIM_OCPOLARITY_HIGH;
	sConfigOC.OCNPolarity = TIM_OCNPOLARITY_HIGH;
	sConfigOC.OCFastMode = TIM_OCFAST_DISABLE;
	sConfigOC.OCIdleState = TIM_OCIDLESTATE_RESET;
	sConfigOC.OCNIdleState = TIM_OCNIDLESTATE_RESET;
	if (HAL_TIM_PWM_ConfigChannel(&htim8, &sConfigOC, TIM_CHANNEL_3) != HAL_OK)
	{
		Error_Handler();
	}
	__HAL_TIM_DISABLE_OCxPRELOAD(&htim8, TIM_CHANNEL_3);
	sBreakDeadTimeConfig.OffStateRunMode = TIM_OSSR_DISABLE;
	sBreakDeadTimeConfig.OffStateIDLEMode = TIM_OSSI_DISABLE;
	sBreakDeadTimeConfig.LockLevel = TIM_LOCKLEVEL_OFF;
	sBreakDeadTimeConfig.DeadTime = 1;
	sBreakDeadTimeConfig.BreakState = TIM_BREAK_DISABLE;
	sBreakDeadTimeConfig.BreakPolarity = TIM_BREAKPOLARITY_HIGH;
	sBreakDeadTimeConfig.BreakFilter = 0;
	sBreakDeadTimeConfig.BreakAFMode = TIM_BREAK_AFMODE_INPUT;
	sBreakDeadTimeConfig.Break2State = TIM_BREAK2_DISABLE;
	sBreakDeadTimeConfig.Break2Polarity = TIM_BREAK2POLARITY_HIGH;
	sBreakDeadTimeConfig.Break2Filter = 0;
	sBreakDeadTimeConfig.Break2AFMode = TIM_BREAK_AFMODE_INPUT;
	sBreakDeadTimeConfig.AutomaticOutput = TIM_AUTOMATICOUTPUT_DISABLE;
	if (HAL_TIMEx_ConfigBreakDeadTime(&htim8, &sBreakDeadTimeConfig) != HAL_OK)
	{
		Error_Handler();
	}
	HAL_TIM_MspPostInit(&htim8);

}

static void MX_TIM15_Init(void)
{

	TIM_ClockConfigTypeDef sClockSourceConfig =
	{ 0 };
	TIM_MasterConfigTypeDef sMasterConfig =
	{ 0 };
	TIM_OC_InitTypeDef sConfigOC =
	{ 0 };
	TIM_BreakDeadTimeConfigTypeDef sBreakDeadTimeConfig =
	{ 0 };

	htim15.Instance = TIM15;
	htim15.Init.Prescaler = 9;
	htim15.Init.CounterMode = TIM_COUNTERMODE_UP;
	htim15.Init.Period = 16999;
	htim15.Init.ClockDivision = TIM_CLOCKDIVISION_DIV1;
	htim15.Init.RepetitionCounter = 0;
	htim15.Init.AutoReloadPreload = TIM_AUTORELOAD_PRELOAD_DISABLE;
	if (HAL_TIM_Base_Init(&htim15) != HAL_OK)
	{
		Error_Handler();
	}
	sClockSourceConfig.ClockSource = TIM_CLOCKSOURCE_INTERNAL;
	if (HAL_TIM_ConfigClockSource(&htim15, &sClockSourceConfig) != HAL_OK)
	{
		Error_Handler();
	}
	if (HAL_TIM_PWM_Init(&htim15) != HAL_OK)
	{
		Error_Handler();
	}
	sMasterConfig.MasterOutputTrigger = TIM_TRGO_RESET;
	sMasterConfig.MasterSlaveMode = TIM_MASTERSLAVEMODE_DISABLE;
	if (HAL_TIMEx_MasterConfigSynchronization(&htim15, &sMasterConfig) != HAL_OK)
	{
		Error_Handler();
	}
	sConfigOC.OCMode = TIM_OCMODE_PWM1;
	sConfigOC.Pulse = 0;
	sConfigOC.OCPolarity = TIM_OCPOLARITY_HIGH;
	sConfigOC.OCNPolarity = TIM_OCNPOLARITY_HIGH;
	sConfigOC.OCFastMode = TIM_OCFAST_DISABLE;
	sConfigOC.OCIdleState = TIM_OCIDLESTATE_RESET;
	sConfigOC.OCNIdleState = TIM_OCNIDLESTATE_RESET;
	if (HAL_TIM_PWM_ConfigChannel(&htim15, &sConfigOC, TIM_CHANNEL_1) != HAL_OK)
	{
		Error_Handler();
	}
	__HAL_TIM_DISABLE_OCxPRELOAD(&htim15, TIM_CHANNEL_1);
	sBreakDeadTimeConfig.OffStateRunMode = TIM_OSSR_DISABLE;
	sBreakDeadTimeConfig.OffStateIDLEMode = TIM_OSSI_DISABLE;
	sBreakDeadTimeConfig.LockLevel = TIM_LOCKLEVEL_OFF;
	sBreakDeadTimeConfig.DeadTime = 0;
	sBreakDeadTimeConfig.BreakState = TIM_BREAK_DISABLE;
	sBreakDeadTimeConfig.BreakPolarity = TIM_BREAKPOLARITY_HIGH;
	sBreakDeadTimeConfig.BreakFilter = 0;
	sBreakDeadTimeConfig.AutomaticOutput = TIM_AUTOMATICOUTPUT_DISABLE;
	if (HAL_TIMEx_ConfigBreakDeadTime(&htim15, &sBreakDeadTimeConfig) != HAL_OK)
	{
		Error_Handler();
	}
	HAL_TIM_MspPostInit(&htim15);

}

static void MX_TIM16_Init(void)
{

	TIM_IC_InitTypeDef sConfigIC =
	{ 0 };

	htim16.Instance = TIM16;
	htim16.Init.Prescaler = 0;
	htim16.Init.CounterMode = TIM_COUNTERMODE_UP;
	htim16.Init.Period = 65535;
	htim16.Init.ClockDivision = TIM_CLOCKDIVISION_DIV4;
	htim16.Init.RepetitionCounter = 0;
	htim16.Init.AutoReloadPreload = TIM_AUTORELOAD_PRELOAD_ENABLE;
	if (HAL_TIM_Base_Init(&htim16) != HAL_OK)
	{
		Error_Handler();
	}
	if (HAL_TIM_IC_Init(&htim16) != HAL_OK)
	{
		Error_Handler();
	}
	sConfigIC.ICPolarity = TIM_INPUTCHANNELPOLARITY_RISING;
	sConfigIC.ICSelection = TIM_ICSELECTION_DIRECTTI;
	sConfigIC.ICPrescaler = TIM_ICPSC_DIV1;
	sConfigIC.ICFilter = 0;
	if (HAL_TIM_IC_ConfigChannel(&htim16, &sConfigIC, TIM_CHANNEL_1) != HAL_OK)
	{
		Error_Handler();
	}

}

static void MX_USART2_UART_Init(void)
{

	huart2.Instance = USART2;
	huart2.Init.BaudRate = 115200;
	huart2.Init.WordLength = UART_WORDLENGTH_8B;
	huart2.Init.StopBits = UART_STOPBITS_1;
	huart2.Init.Parity = UART_PARITY_NONE;
	huart2.Init.Mode = UART_MODE_TX_RX;
	huart2.Init.HwFlowCtl = UART_HWCONTROL_NONE;
	huart2.Init.OverSampling = UART_OVERSAMPLING_16;
	huart2.Init.OneBitSampling = UART_ONE_BIT_SAMPLE_DISABLE;
	huart2.Init.ClockPrescaler = UART_PRESCALER_DIV1;
	huart2.AdvancedInit.AdvFeatureInit = UART_ADVFEATURE_NO_INIT;
	if (HAL_UART_Init(&huart2) != HAL_OK)
	{
		Error_Handler();
	}
	if (HAL_UARTEx_SetTxFifoThreshold(&huart2, UART_TXFIFO_THRESHOLD_1_8) != HAL_OK)
	{
		Error_Handler();
	}
	if (HAL_UARTEx_SetRxFifoThreshold(&huart2, UART_RXFIFO_THRESHOLD_1_8) != HAL_OK)
	{
		Error_Handler();
	}
	if (HAL_UARTEx_DisableFifoMode(&huart2) != HAL_OK)
	{
		Error_Handler();
	}

}

static void MX_DMA_Init(void)
{

	/* DMA controller clock enable */
	__HAL_RCC_DMAMUX1_CLK_ENABLE();
	__HAL_RCC_DMA1_CLK_ENABLE();
	__HAL_RCC_DMA2_CLK_ENABLE();

	/* DMA interrupt init */
	/* DMA1_Channel1_IRQn interrupt configuration */
	HAL_NVIC_SetPriority(DMA1_Channel1_IRQn, 0, 0);
	HAL_NVIC_EnableIRQ(DMA1_Channel1_IRQn);
	/* DMA1_Channel2_IRQn interrupt configuration */
	HAL_NVIC_SetPriority(DMA1_Channel2_IRQn, 0, 0);
	HAL_NVIC_EnableIRQ(DMA1_Channel2_IRQn);
	/* DMA1_Channel3_IRQn interrupt configuration */
	HAL_NVIC_SetPriority(DMA1_Channel3_IRQn, 0, 0);
	HAL_NVIC_EnableIRQ(DMA1_Channel3_IRQn);
	/* DMA2_Channel1_IRQn interrupt configuration */
	HAL_NVIC_SetPriority(DMA2_Channel1_IRQn, 0, 0);
	HAL_NVIC_EnableIRQ(DMA2_Channel1_IRQn);
	/* DMA2_Channel2_IRQn interrupt configuration */
	HAL_NVIC_SetPriority(DMA2_Channel2_IRQn, 0, 0);
	HAL_NVIC_EnableIRQ(DMA2_Channel2_IRQn);

}

static void MX_GPIO_Init(void)
{
	GPIO_InitTypeDef GPIO_InitStruct =
	{ 0 };

	/* GPIO Ports Clock Enable */
	__HAL_RCC_GPIOC_CLK_ENABLE();
	__HAL_RCC_GPIOF_CLK_ENABLE();
	__HAL_RCC_GPIOA_CLK_ENABLE();
	__HAL_RCC_GPIOB_CLK_ENABLE();

	/*Configure GPIO pin Output Level */
	HAL_GPIO_WritePin(GPIOC, LED_COMM_Pin | LED_STATUS_Pin, GPIO_PIN_RESET);

	/*Configure GPIO pin Output Level */
	HAL_GPIO_WritePin(GPIOA, USART_RX_TX_Pin | BUZZER_Pin, GPIO_PIN_RESET);

	/*Configure GPIO pin Output Level */
	HAL_GPIO_WritePin(CS_MAX31855_GPIO_Port, CS_MAX31855_Pin, GPIO_PIN_SET);

	/*Configure GPIO pin Output Level */
	HAL_GPIO_WritePin(RELAY_INRUSH_GPIO_Port, RELAY_INRUSH_Pin, GPIO_PIN_RESET);

	/*Configure GPIO pin Output Level */
	HAL_GPIO_WritePin(FAULT_CLR_GPIO_Port, FAULT_CLR_Pin, GPIO_PIN_SET);

	/*Configure GPIO pins : LED_COMM_Pin LED_STATUS_Pin */
	GPIO_InitStruct.Pin = LED_COMM_Pin | LED_STATUS_Pin;
	GPIO_InitStruct.Mode = GPIO_MODE_OUTPUT_PP;
	GPIO_InitStruct.Pull = GPIO_NOPULL;
	GPIO_InitStruct.Speed = GPIO_SPEED_FREQ_LOW;
	HAL_GPIO_Init(GPIOC, &GPIO_InitStruct);

	/*Configure GPIO pins : USART_RX_TX_Pin CS_MAX31855_Pin BUZZER_Pin */
	GPIO_InitStruct.Pin = USART_RX_TX_Pin | CS_MAX31855_Pin | BUZZER_Pin;
	GPIO_InitStruct.Mode = GPIO_MODE_OUTPUT_PP;
	GPIO_InitStruct.Pull = GPIO_NOPULL;
	GPIO_InitStruct.Speed = GPIO_SPEED_FREQ_LOW;
	HAL_GPIO_Init(GPIOA, &GPIO_InitStruct);

	/*Configure GPIO pins : RELAY_INRUSH_Pin FAULT_CLR_Pin */
	GPIO_InitStruct.Pin = RELAY_INRUSH_Pin | FAULT_CLR_Pin;
	GPIO_InitStruct.Mode = GPIO_MODE_OUTPUT_PP;
	GPIO_InitStruct.Pull = GPIO_NOPULL;
	GPIO_InitStruct.Speed = GPIO_SPEED_FREQ_LOW;
	HAL_GPIO_Init(GPIOB, &GPIO_InitStruct);

	/*Configure GPIO pins : PG_MPQ_Pin FAULT_SD_Pin */
	GPIO_InitStruct.Pin = PG_MPQ_Pin | FAULT_SD_Pin;
	GPIO_InitStruct.Mode = GPIO_MODE_IT_FALLING;
	GPIO_InitStruct.Pull = GPIO_NOPULL;
	HAL_GPIO_Init(GPIOB, &GPIO_InitStruct);

	/*Configure GPIO pins : FAN2_RPM_Pin SY_FLT_Pin */
	GPIO_InitStruct.Pin = FAN2_RPM_Pin | SY_FLT_Pin;
	GPIO_InitStruct.Mode = GPIO_MODE_INPUT;
	GPIO_InitStruct.Pull = GPIO_NOPULL;
	HAL_GPIO_Init(GPIOB, &GPIO_InitStruct);

	/* EXTI interrupt init*/
	HAL_NVIC_SetPriority(EXTI9_5_IRQn, 0, 0);
	HAL_NVIC_EnableIRQ(EXTI9_5_IRQn);

	HAL_NVIC_SetPriority(EXTI15_10_IRQn, 0, 0);
	HAL_NVIC_EnableIRQ(EXTI15_10_IRQn);

}

/* USER CODE BEGIN 4 */
void HAL_GPIO_EXTI_Callback(uint16_t GPIO_Pin)
{
	/* Pino power good do MPQ */
	if (GPIO_Pin == PG_MPQ_Pin)
	{
		if (HAL_GPIO_ReadPin(PG_MPQ_GPIO_Port, PG_MPQ_Pin) == LOW)
		{
			Status.Errors.MPQNpg = true;
		}
		else
		{
			Status.Errors.MPQNpg = false;
			SetError(); /* Verify if exist error */
		}
	}

	/* Pin fault */
	if (GPIO_Pin == FAULT_SD_Pin && HAL_GPIO_ReadPin(FAULT_SD_GPIO_Port, FAULT_SD_Pin) == LOW)
	{
		Hw_Buck_Deinit();
		Status.Errors.Fault = true;
	}
}

void HAL_TIM_PeriodElapsedCallback(TIM_HandleTypeDef *htim)
{
	if (htim == &htim2)
	{
		InterruptControl_MAX31855();

		SetError(); /* Verify if exist error */
		StatusLEDControl((uint8_t) sStatusPower.Flags.Error);

		FDUSART_InterruptControl();

		if (Cnt1ms > USHRT_MAX - 1)
			Cnt1ms = 0;
		else
			Cnt1ms++;

		if (Cnt1ms % 1000 == 0)
		{
			if (++Cnt60s >= 60)
			{
				Cnt60s = 0;
				if (++Status.HourmeterMinutes >= 60)
				{
					Status.HourmeterHours++;
					Status.HourmeterMinutes = 0;
				}
			}

			Status.TemperatureOven = (int16_t) ((float) GetTemperatureExternal_MAX31855() * 100.0);

			FDUSART_SendMessage(FullDuplexSystem, (uint8_t) COMM_GET_STATUS, (uint8_t*) &Status, sizeof(Status));
		}

		/* Power on relay inrush */
		if (CntRelayInrush >= RELAY_INRUSH)
			HAL_GPIO_WritePin(RELAY_INRUSH_GPIO_Port, RELAY_INRUSH_Pin, HIGH);
		else
			CntRelayInrush++;

		/* Erro Fan RPM cooler */
		if (CntFanPCB >= FAN_PCB_TIMEOUT)
		{
			Status.Errors.ErrorFanPcb = true;
			IC_FanPCB_RPM = 0;
			IC_FanPCB_Frequency = 0;
		}
		else
		{
			CntFanPCB++;
		}

		/* Erro Fan RPM cooler */
		if (CntFan1 >= FAN_1_AND_2_TIMEOUT)
		{
			Status.Errors.ErrorFan1 = true;
			IC_Fan1_RPM = 0;
			IC_Fan1_Frequency = 0;
		}
		else
		{
			if (HAL_TIM_ReadCapturedValue(&htim1, TIM_CHANNEL_2) > 0)  //Se o Duty for maior que 0 começa a contar o tempo de timeout
				CntFan1++;
			else
				CntFan1 = 0;
		}

		/* PoweeDown */
		if (ValuePD < POWERDOWN_VALUE)
		{
			if (CntTimeoutPD > TIMEOUT_PD)
			{
				Status.Errors.Powerdown = true;
			}
			else
			{
				CntTimeoutPD++;
			}
		}
		else
		{
			Status.Errors.Powerdown = false;
			CntTimeoutPD = 0;
		}

		/* Overvoltage, Undervoltage */
		if (Status.PowerVoltage > OVERVOLTAGE_VALUE)
		{
			if (CntTimeoutOvervoltage > TIMEOUT_OVERVOLTAGE)
			{
				Status.Errors.Overvoltage = true;
			}
			else
			{
				CntTimeoutOvervoltage++;
			}
		}

		else if (Status.PowerVoltage > LOW_OPERATION && Status.PowerVoltage <= UNDERVOLTAGE_VALUE) // Undervoltage
		{
			if (CntTimeoutUndervoltage > TIMEOUT_OVERVOLTAGE)
			{
				Status.Errors.Undervoltage = true;
			}
			else
			{
				CntTimeoutUndervoltage++;
			}
		}
		else
		{
			Status.Errors.Undervoltage = false;
			Status.Errors.Overvoltage = false;
			CntTimeoutOvervoltage = 0;
			CntTimeoutUndervoltage = 0;
		}
	}
	else if (htim == &htim16)
	{
		if (IC_FanPCB_OvfTimer < USHRT_MAX)
			IC_FanPCB_OvfTimer++;
	}
	else if (htim == &htim1)
	{
		if (IC_Fan1_OvfTimer < USHRT_MAX)
			IC_Fan1_OvfTimer++;
	}
}

void DMACallbackADC1(DMA_HandleTypeDef *hdma)
{

	if (CntAdValueVREG >= BUFFER_VREG)
	{
		sStatusPower.Flags.CalculateVREG = true;
		CntAdValueVREG = 0;
	}
	else if (sStatusPower.Flags.CalculateVREG == false)
	{
		AdValueVREG[CntAdValueVREG++] = Adc1Val[0];
	}

	if (CntAdValueNTC >= BUFFER_NTC)
	{
		//asm("NOP");
		sStatusPower.Flags.CalculateNTC = true;
		CntAdValueNTC = 0;
	}
	else if (sStatusPower.Flags.CalculateNTC == false)
	{
		AdValueNTC[CntAdValueNTC++] = Adc1Val[1];
	}
}
void DMACallbackADC2(DMA_HandleTypeDef *hdma)
{
	if (CntAdValueCURR >= BUFFER_CURR)
	{
		sStatusPower.Flags.CalculateCURR = true;
		CntAdValueCURR = 0;
	}
	else if (sStatusPower.Flags.CalculateCURR == false)
	{
		AdValueCURR[CntAdValueCURR++] = Adc2Val[0];
	}

	if (CntAdValuePD >= BUFFER_PD)
	{
		sStatusPower.Flags.CalculatePD = true;
		CntAdValuePD = 0;
	}
	else if (sStatusPower.Flags.CalculatePD == false)
	{
		AdValuePD[CntAdValuePD++] = Adc2Val[1];
	}

	if (CntAdValueVBUS >= BUFFER_VBUS)
	{
		sStatusPower.Flags.CalculateVBUS = true;
		CntAdValueVBUS = 0;
	}
	else if (sStatusPower.Flags.CalculateVBUS == false)
	{
		AdValueVBUS[CntAdValueVBUS++] = Adc2Val[2];
	}

}

static void StatusLEDControl(uint8_t ErrorCode)
{
	CntStatusLED++;

	if (ErrorCode == (uint8_t) ERROR_NONE)
	{
		if (CntStatusLED >= PERIOD_LED)
		{
			HAL_GPIO_TogglePin(LED_STATUS_GPIO_Port, LED_STATUS_Pin);
			CntStatusLED = 0;
		}
	}
	else
	{
		if (CntStatusLED <= PERIOD_LED_ERROR && CntStatusLEDError < (uint8_t) ErrorCode)
		{
			HAL_GPIO_WritePin(LED_STATUS_GPIO_Port, LED_STATUS_Pin, GPIO_PIN_SET);
		}
		else if (CntStatusLEDError < (uint8_t) ErrorCode)
		{
			HAL_GPIO_WritePin(LED_STATUS_GPIO_Port, LED_STATUS_Pin, GPIO_PIN_RESET);

			if (CntStatusLED >= PERIOD_LED_ERROR * 2)
			{
				CntStatusLED = 0;
				CntStatusLEDError++;
			}
		}
		else
		{
			if (CntStatusLED >= PERIOD_LED)
			{
				CntStatusLED = 0;
				CntStatusLEDError = 0;
			}
		}

	}
}

void HAL_TIM_IC_CaptureCallback(TIM_HandleTypeDef *htim)
{
	if (htim->Instance == TIM16) //Fan RPM PCB
	{
		CntFanPCB = 0;
		if (IC_FanPCB_IsFirstCaptured == false)
		{
			IC_FanPCB_OvfTimer = 0;
			IC_FanPCB_Value1 = HAL_TIM_ReadCapturedValue(&htim16, TIM_CHANNEL_1);
			IC_FanPCB_IsFirstCaptured = true;
		}
		else if (IC_FanPCB_IsFirstCaptured == true)
		{
			IC_FanPCB_Value2 = HAL_TIM_ReadCapturedValue(&htim16, TIM_CHANNEL_1);
			if (IC_FanPCB_Value2 > IC_FanPCB_Value1)
			{
				IC_FanPCB_Difference = (IC_FanPCB_Value2 + (IC_FanPCB_OvfTimer * 0xFFFF)) - IC_FanPCB_Value1;
			}
			else if (IC_FanPCB_Value2 < IC_FanPCB_Value1)
			{
				IC_FanPCB_Difference = ((0xFFFF - IC_FanPCB_Value1) + (IC_FanPCB_OvfTimer * 0xFFFF) + IC_FanPCB_Value2) + 1;
			}
			else
			{
				Error_Handler();
			}
			//Frequency = TIM3 CLOCK / Difference
			IC_FanPCB_Frequency = HAL_RCC_GetPCLK1Freq() / IC_FanPCB_Difference;
			IC_FanPCB_RPM = IC_FanPCB_Frequency * 60;
			Status.FanRPMPCB = IC_FanPCB_RPM;
			IC_FanPCB_IsFirstCaptured = false;
		}

	}
	if (htim->Instance == TIM1) //Fan RPM Fan1
	{
		CntFan1 = 0;
		if (IC_Fan1_IsFirstCaptured == false)
		{
			IC_Fan1_OvfTimer = 0;
			IC_Fan1_Value1 = HAL_TIM_ReadCapturedValue(&htim1, TIM_CHANNEL_1);
			IC_Fan1_IsFirstCaptured = true;
		}
		else if (IC_Fan1_IsFirstCaptured == true)
		{
			IC_Fan1_Value2 = HAL_TIM_ReadCapturedValue(&htim1, TIM_CHANNEL_1);
			if (IC_Fan1_Value2 > IC_Fan1_Value1)
			{
				IC_Fan1_Difference = (IC_Fan1_Value2 + (IC_Fan1_OvfTimer * 0xFFFF)) - IC_Fan1_Value1;
			}
			else if (IC_Fan1_Value2 < IC_Fan1_Value1)
			{
				IC_Fan1_Difference = ((0xFFFF - IC_Fan1_Value1) + (IC_Fan1_OvfTimer * 0xFFFF) + IC_Fan1_Value2) + 1;
			}
			else
			{
				Error_Handler();
			}
			//Frequency = TIM3 CLOCK / Difference
			IC_Fan1_Frequency = HAL_RCC_GetPCLK1Freq() / IC_Fan1_Difference;
			IC_Fan1_RPM = IC_Fan1_Frequency * 60;
			Status.FanRPMOven1 = IC_Fan1_RPM;
			IC_Fan1_IsFirstCaptured = false;
		}

		Status.FanRPMOven2 = 0; //Todo: Create Calculate Fan2
	}
}
static void Hw_Buck_Init(void)
{

	GPIO_InitTypeDef GPIO_InitStruct =
	{ 0 };

	if (HAL_GPIO_ReadPin(FAULT_SD_GPIO_Port, FAULT_SD_Pin) == HIGH)
	{
		HAL_GPIO_WritePin(FAULT_CLR_GPIO_Port, FAULT_CLR_Pin, GPIO_PIN_SET);

		/* Definindo FAULT SD como pino de entrada com interrupção */
		/* Estrutura */
		GPIO_InitStruct.Pin = FAULT_SD_Pin;
		GPIO_InitStruct.Mode = GPIO_MODE_IT_FALLING;
		GPIO_InitStruct.Pull = GPIO_NOPULL;
		HAL_GPIO_Init(GPIOB, &GPIO_InitStruct);

	}
}
static void Hw_Buck_Deinit(void)
{
	GPIO_InitTypeDef GPIO_InitStruct =
	{ 0 };

	/* Setando Fault Clear para baixo */
	HAL_GPIO_WritePin(FAULT_CLR_GPIO_Port, FAULT_CLR_Pin, GPIO_PIN_RESET);

	/* Definindo FAULT SD como pino de saída e forçando para 0V*/
	/* Estrutura */
	GPIO_InitStruct.Pin = FAULT_SD_Pin;
	GPIO_InitStruct.Mode = GPIO_MODE_OUTPUT_PP;
	GPIO_InitStruct.Pull = GPIO_NOPULL;
	GPIO_InitStruct.Speed = GPIO_SPEED_FREQ_LOW;
	HAL_GPIO_Init(GPIOB, &GPIO_InitStruct);

	/* Forçando FAULT SD para 0V */
	HAL_GPIO_WritePin(FAULT_SD_GPIO_Port, FAULT_SD_Pin, GPIO_PIN_RESET);
}

static void SetOutputVoltage(uint16_t OutVoltage)
{
	uint16_t DutyCalculate = 0;
	uint16_t MaxValueDuty = htim8.Init.Period - 75;

	if (Status.PowerVoltage > 0)
	{
		DutyCalculate = ((uint32_t) (OutVoltage * htim8.Init.Period) / Status.PowerVoltage);

		if (OutVoltage > ValueVBUS || DutyCalculate > MaxValueDuty)
			DutyCalculate = MaxValueDuty;

		__HAL_TIM_SET_COMPARE(&htim8, TIM_CHANNEL_3, DutyCalculate);
		asm("NOP");
	}

}

static void SetError(void)
{
	if (sStatusPower.Flags.Error == ERROR_NONE)
	{
		if (Status.Errors.Fault)
			sStatusPower.Flags.Error = ERROR_FAULT;
		else if (Status.Errors.Powerdown)
			sStatusPower.Flags.Error = ERROR_POWERDOWN;
		else if (Status.Errors.Undervoltage)
			sStatusPower.Flags.Error = ERROR_UNDERVOLTAGE;
		else if (Status.Errors.Overvoltage)
			sStatusPower.Flags.Error = ERROR_OVERVOLTAGE;
		else if (Status.Errors.MPQNpg)
			sStatusPower.Flags.Error = ERROR_MPQ_NPG;
		else if (Status.Errors.ErrorFanPcb)
			sStatusPower.Flags.Error = ERROR_FAN_PCB;
		else if (Status.Errors.ErrorFan1)
			sStatusPower.Flags.Error = ERROR_FAN1;
		else if (Status.Errors.ErrorNTCDissipator)
			sStatusPower.Flags.Error = ERROR_NTC_DISSIPATOR;
	}
	else
		Hw_Buck_Deinit();

	if (Status.Errors.ExistError == 0) // Se não houver nenhum erro, limpa erro
		sStatusPower.Flags.Error = ERROR_NONE; /* Clear Error */
}

/* USER CODE END 4 */

void Error_Handler(void)
{
	__disable_irq();
	while (1)
	{
	}
}
